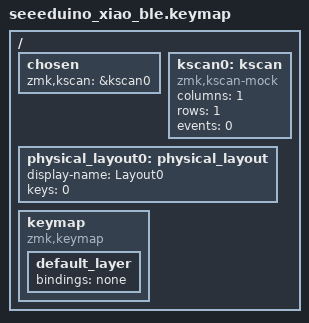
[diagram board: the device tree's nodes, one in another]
#include <behaviors.dtsi>
#include <dt-bindings/zmk/keys.h>

/ {
    chosen {
        zmk,kscan = &kscan0;
    };

    kscan0: kscan {
        compatible = "zmk,kscan-mock";
        columns = <1>;
        rows = <1>;
        events = <0>;
    };

    physical_layout0: physical_layout {
        display-name = "Layout0";
        keys = <0>;
    };

    keymap {
        compatible = "zmk,keymap";

        default_layer {
            bindings = <&none>;
        };
    };
};
